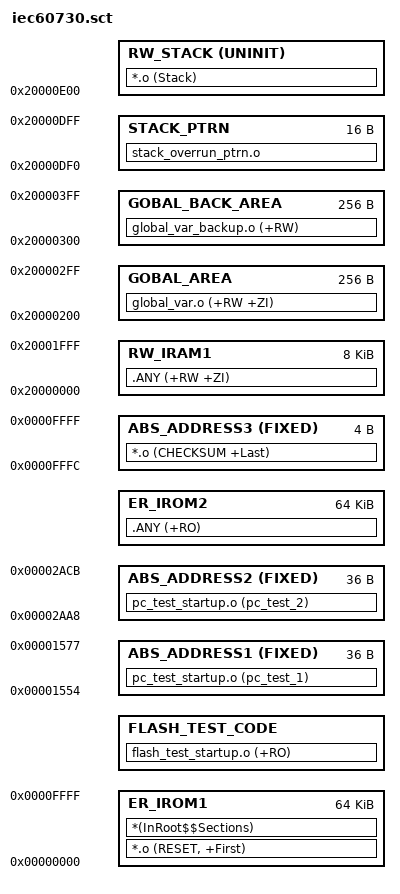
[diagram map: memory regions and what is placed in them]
; *************************************************************
; *** Scatter-Loading Description File generated by uVision ***
; *************************************************************

LR_IROM1 0x00000000         {    ; load region
  ER_IROM1 0x00000000 0x00010000  {  ; load address = execution address
   *.o (RESET, +First)
   *(InRoot$$Sections)
;   *.o (CHECKSUM, +Last)   
  }
  
  FLASH_TEST_CODE +0
  {
    flash_test_startup.o (+RO)
  }
  
;  ABS_ADDRESS1 0x1F400 FIXED 4 {
  ABS_ADDRESS1 0x1554 FIXED 36 {
    pc_test_startup.o (pc_test_1)
  }
  
;  ABS_ADDRESS2 0x410 FIXED 8 {
  ABS_ADDRESS2 0x2AA8 FIXED 36 {
    pc_test_startup.o (pc_test_2)
  }
  
  ER_IROM2 +0 0x00010000  {  	; load address = execution address
   .ANY (+RO)
  } 



  RW_IRAM1 0x20000000 0x0002000  {             ; RW data
   .ANY (+RW +ZI)
  }
  
  GOBAL_AREA 0x20000200 256 	; RO data
  {
    global_var.o (+RW +ZI)
  }
  
  GOBAL_BACK_AREA 0x20000300 256 	; RO data
  {
    global_var_backup.o (+RW)
  }
  
  RW_STACK 0x20001000-0x200 UNINIT ALIGN 16    ; RW data - Stack
  {
    *.o (Stack)             ; stack size is 0x0200
  }
  
  STACK_PTRN 0x20001000-0x0200-0x0010 0x0010    ; RO data
  {  
    stack_overrun_ptrn.o
  }
  ABS_ADDRESS3 (0x10000-0x4) FIXED 4 {
    *.o (CHECKSUM +Last)   
  }
}

